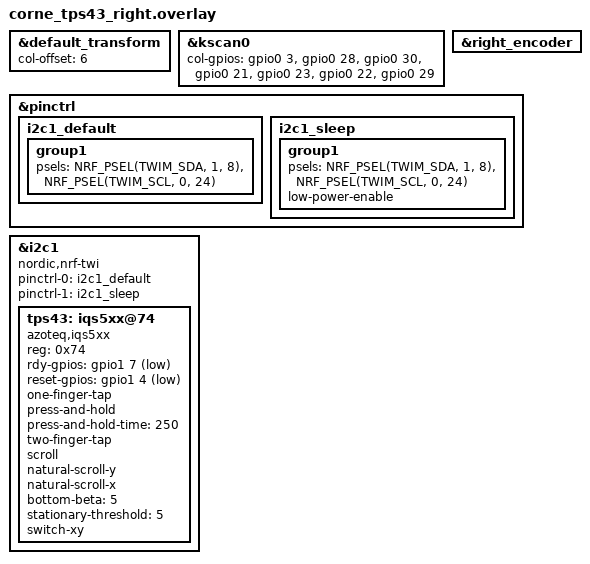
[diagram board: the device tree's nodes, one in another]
/*
 * Copyright (c) 2025 The ZMK Contributors
 *
 * SPDX-License-Identifier: MIT
 */

#include "corne_tps43.dtsi"

&default_transform {
    col-offset = <6>;
};

&kscan0 {
    col-gpios
        = <&gpio0 3 GPIO_ACTIVE_HIGH>
        , <&gpio0 28 GPIO_ACTIVE_HIGH>
        , <&gpio0 30 GPIO_ACTIVE_HIGH>
        , <&gpio0 21 GPIO_ACTIVE_HIGH>
        , <&gpio0 23 GPIO_ACTIVE_HIGH>
        , <&gpio0 22 GPIO_ACTIVE_HIGH>
        , <&gpio0 29 GPIO_ACTIVE_HIGH>
        ;
};

&right_encoder {
    status = "okay";
};

&pinctrl {
    i2c1_default: i2c1_default {
        group1 {
            psels = <NRF_PSEL(TWIM_SDA, 1, 8)>,
                <NRF_PSEL(TWIM_SCL, 0, 24)>;
        };
    };

    i2c1_sleep: i2c1_sleep {
        group1 {
            psels = <NRF_PSEL(TWIM_SDA, 1, 8)>,
                <NRF_PSEL(TWIM_SCL, 0, 24)>;
            low-power-enable;
        };
    };
};

&i2c1 {
    status = "okay";
    compatible = "nordic,nrf-twi";
    pinctrl-0 = <&i2c1_default>;
    pinctrl-1 = <&i2c1_sleep>;
    pinctrl-names = "default", "sleep";

    tps43: iqs5xx@74 {
        status = "okay";
        compatible = "azoteq,iqs5xx";
        reg = <0x74>;

        rdy-gpios = <&gpio1 7 GPIO_ACTIVE_LOW>;  /* Interrupt pin */
        reset-gpios = <&gpio1 4 GPIO_ACTIVE_LOW>;  /* Reset pin */

        /*
         * Potentially non-exhaustive list of configuration options.
         * See: dts/bindings/input/azoteq,iqs5xx-common.yaml for a full list.
         */
        one-finger-tap;
        press-and-hold;
        press-and-hold-time = <250>;
        two-finger-tap;

        scroll;
        natural-scroll-y;
        natural-scroll-x;

        bottom-beta = <5>;
        stationary-threshold = <5>;

        switch-xy;
    };
};
